# AESADV_1.0 register map
Vendor: Texas Instruments
Peripheral module from a debugger description file (folder mspm33c321x).
Registers are 32-bit, access not given, no defined reset value unless marked. A register's access mark holds for its fields unless they carry their own. Offsets are as the file gives them; lines under a group give offsets from that group; [hi:lo] are bit positions; {n}, {i} and the like mark numbered series; 'fields as' and 'values as' point back to an identical list; <NAME> marks a mode.

## AESADVHP
0x480 AESADVHP_CPU_CONNECT_0 — CPU Connect
0x800 AESADVHP_GPRCM group
  0x00 AESADVHP_PWREN rw — Power enable
    [0] ENABLE — Enable the power
      0=DISABLE (Disable Power); 1=ENABLE (Enable Power)
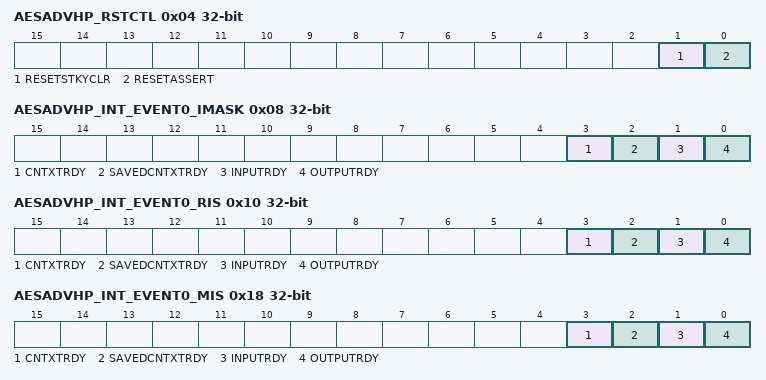
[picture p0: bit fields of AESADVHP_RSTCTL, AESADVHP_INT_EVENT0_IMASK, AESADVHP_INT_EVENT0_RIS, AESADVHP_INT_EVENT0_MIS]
  0x04 AESADVHP_RSTCTL rw — Reset Control
    [1] RESETSTKYCLR — Clear the RESETSTKY bit in the STAT register
      0=NOP (Writing 0 has no effect); 1=CLR (Clear reset sticky bit)
    [0] RESETASSERT — Assert reset to the peripheral
      0=NOP (Writing 0 has no effect); 1=ASSERT (Assert reset)
  0x14 AESADVHP_STAT ro — Status Register
    [16] RESETSTKY — This bit indicates, if the peripheral was reset, since this bit was cleared by RESETSTKYCLR in the RSTCTL register
      0=NORES (The peripheral has not been reset since this bit was last cleared by RESETSTKYCLR in the RSTCTL register); 1=RESET (The peripheral was reset since the last bit clear)
0x1018 AESADVHP_PDBGCTL ro — Peripheral Debug Control
  [0] FREE — Free run control
    1=RUN (The peripheral ignores the state of the Core Halted input)
0x1020 AESADVHP_INT_EVENT0 group
  0x00 AESADVHP_INT_EVENT0_IIDX ro — Interrupt Index Register
    [7:0] STAT — Interrupt index status
      0=NO_INTR (No interrupt pending); 1=OUTPUTRDY (This indicates that the core has an output available to be read out. This should not be used if DMA handshake is used (AES_DMA_HS.DMA_DATA_ACK set to 1)); 2=INPUTRDY (This indicates that the engine can take new input. This should not be used if DMA handshake is used (AES_DMA_HS.DMA_DATA_ACK set to 1)); 3=SAVEDCNTXTRDY (This bit indicates that an AES authentication TAG and/or IV block(s) is/are available for the CPU to retrieve. This bit is only asserted if the save_context bit is set to 1b. The bit is mutually exclusive with the context_ready bit.); 4=CNTXTRDY (This bit indicates that the context data registers can be overwritten, and the CPU is permitted to write new context.)
  0x08 AESADVHP_INT_EVENT0_IMASK rw — Interrupt mask
    [all] fields
      0=CLR (Clear Interrupt Mask); 1=SET (Set Interrrupt Mask)
    [3] CNTXTRDY — This bit indicates that the context data registers can be overwritten, and the CPU is permitted to write next context.
    [2] SAVEDCNTXTRDY — This bit indicates that an AES authentication TAG and/or IV block(s) is/are available for the CPU to retrieve. This bit is only asserted if the save_context bit is set to 1b. The bit is mutually exclusive with the context_ready bit.
    [1] INPUTRDY — This indicates that the engine can take new input. This should not be used if DMA handshake is used (AES_DMA_HS.DMA_DATA_ACK set to 1)
    [0] OUTPUTRDY — This indicates that the core has an output available to be read out. This should not be used if DMA handshake is used (AES_DMA_HS.DMA_DATA_ACK set to 1)
  0x10 AESADVHP_INT_EVENT0_RIS rw — Raw interrupt status
    [3] CNTXTRDY — This bit indicates that the context data registers can be overwritten, and the CPU is permitted to write next context.
      0=CLR (Clear Interrupt Mask); 1=SET (Set Interrrupt Mask)
    [2] SAVEDCNTXTRDY — This bit indicates that an AES authentication TAG and/or IV block(s) is/are available for the CPU to retrieve. This bit is only asserted if the save_context bit is set to 1b. The bit is mutually exclusive with the context_ready bit.
      0=CLR (Clear Interrupt Mask); 1=SET (Set Interrrupt Mask)
    [1] INPUTRDY — This indicates that the engine can take new input. This should not be used if DMA handshake is used (AES_DMA_HS.DMA_DATA_ACK set to 1)
      0=CLR (Clear Interrupt Mask); 1=SET (Set Interrrupt Mask)
    [0] OUTPUTRDY — This indicates that the core has an output available to be read out. This should not be used if DMA handshake is used (AES_DMA_HS.DMA_DATA_ACK set to 1)
      0=CLR (Interrupt did not occur); 1=SET (Interrupt occured)
  0x18 AESADVHP_INT_EVENT0_MIS rw — Masked interrupt status
    fields as AESADVHP_INT_EVENT0.AESADVHP_INT_EVENT0_RIS
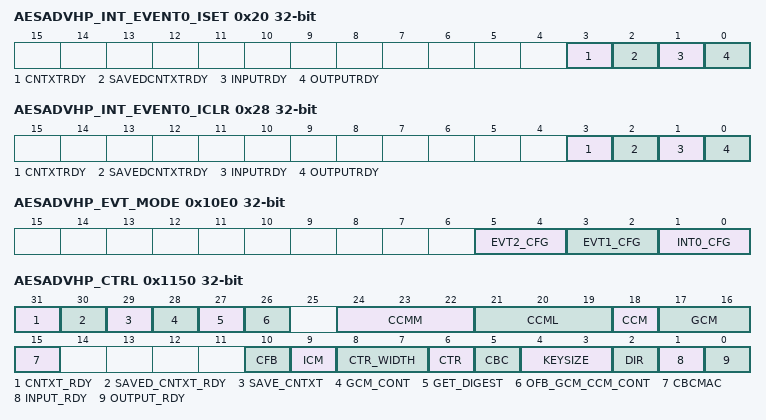
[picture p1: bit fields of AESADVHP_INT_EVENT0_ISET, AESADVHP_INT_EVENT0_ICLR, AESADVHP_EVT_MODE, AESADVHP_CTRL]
  0x20 AESADVHP_INT_EVENT0_ISET rw — Interrupt set
    [3] CNTXTRDY — This bit indicates that the context data registers can be overwritten, and the CPU is permitted to write next context.
      0=CLR (Clear Interrupt Mask); 1=SET (Set Interrrupt Mask)
    [2] SAVEDCNTXTRDY — This bit indicates that an AES authentication TAG and/or IV block(s) is/are available for the CPU to retrieve. This bit is only asserted if the save_context bit is set to 1b. The bit is mutually exclusive with the context_ready bit.
      0=CLR (Clear Interrupt Mask); 1=SET (Set Interrrupt Mask)
    [1] INPUTRDY — This indicates that the engine can take new input.This should not be used if DMA handshake is used (AES_DMA_HS.DMA_DATA_ACK set to 1)
      0=CLR (Clear Interrupt Mask); 1=SET (Set Interrrupt Mask)
    [0] OUTPUTRDY — This indicates that the core has an output available to be read out. This should not be used if DMA handshake is used (AES_DMA_HS.DMA_DATA_ACK set to 1)
      0=NO_EFFECT (Writing 0 has no effect); 1=SET (Set Interrupt)
  0x28 AESADVHP_INT_EVENT0_ICLR rw — Interrupt clear
    [3] CNTXTRDY — This bit indicates that the context data registers can be overwritten, and the CPU is permitted to write next context.
      0=CLR (Clear Interrupt Mask); 1=SET (Set Interrrupt Mask)
    [2] SAVEDCNTXTRDY — This bit indicates that an AES authentication TAG and/or IV block(s) is/are available for the CPU to retrieve. This bit is only asserted if the save_context bit is set to 1b. The bit is mutually exclusive with the context_ready bit.
      0=CLR (Clear Interrupt Mask); 1=SET (Set Interrrupt Mask)
    [1] INPUTRDY — This indicates that the engine can take new input. This should not be used if DMA handshake is used (AES_DMA_HS.DMA_DATA_ACK set to 1)
      0=CLR (Clear Interrupt Mask); 1=SET (Set Interrrupt Mask)
    [0] OUTPUTRDY — This indicates that the core has an output available to be read out. This should not be used if DMA handshake is used (AES_DMA_HS.DMA_DATA_ACK set to 1)
      0=NO_EFFECT (Writing 0 has no effect); 1=CLR (Clear Interrupt)
0x1050 AESADVHP_INT_EVENT1 group
  0x00 AESADVHP_INT_EVENT1_IIDX ro — Interrupt Index Register
    [7:0] STAT — Interrupt index status
      0=NO_INTR (No interrupt pending); 1=TRIG0 (AES trigger 0 DMA (Data Input trigger))
  0x08 AESADVHP_INT_EVENT1_IMASK rw — Interrupt mask
    [0] TRIG0 — TRIG0 event mask.
      0=CLR (Clear Interrupt Mask); 1=SET (Set Interrrupt Mask)
  0x10 AESADVHP_INT_EVENT1_RIS rw — Raw interrupt status
    [0] TRIG0 — TRIG0 event
      0=CLR (Interrupt did not occur); 1=SET (Interrupt occured)
  0x18 AESADVHP_INT_EVENT1_MIS rw — Masked interrupt status
    fields as AESADVHP_INT_EVENT1.AESADVHP_INT_EVENT1_RIS
  0x20 AESADVHP_INT_EVENT1_ISET rw — Interrupt set
    [0] TRIG0
      0=NO_EFFECT (Writing 0 has no effect); 1=SET (Set Interrupt)
  0x28 AESADVHP_INT_EVENT1_ICLR rw — Interrupt clear
    [0] TRIG0 — TRIG0 event
      values as AESADVHP_INT_EVENT0.AESADVHP_INT_EVENT0_ICLR.OUTPUTRDY
0x1080 AESADVHP_INT_EVENT2 group
  0x00 AESADVHP_INT_EVENT2_IIDX ro — Interrupt Index Register
    [7:0] STAT — Interrupt index status
      0=NO_INTR (No interrupt pending); 1=TRIG1 (AES DMA Trigger 1 (Data Output trigger))
  0x08 AESADVHP_INT_EVENT2_IMASK rw — Interrupt mask
    [0] TRIG1 — TRIG1 event mask.
      0=CLR (Clear Interrupt Mask); 1=SET (Set Interrrupt Mask)
  0x10 AESADVHP_INT_EVENT2_RIS rw — Raw interrupt status
    [0] TRIG1 — TRIG1 event
      0=CLR (Interrupt did not occur); 1=SET (Interrupt occured)
  0x18 AESADVHP_INT_EVENT2_MIS rw — Masked interrupt status
    fields as AESADVHP_INT_EVENT2.AESADVHP_INT_EVENT2_RIS
  0x20 AESADVHP_INT_EVENT2_ISET rw — Interrupt set
    [0] TRIG1 — TRIG1 event
      0=NO_EFFECT (Writing 0 has no effect); 1=SET (Set Interrupt)
  0x28 AESADVHP_INT_EVENT2_ICLR rw — Interrupt clear
    [0] TRIG1 — TRIG1 event
      values as AESADVHP_INT_EVENT0.AESADVHP_INT_EVENT0_ICLR.OUTPUTRDY
0x10E0 AESADVHP_EVT_MODE ro — Event Mode
  [all] fields
    0=DISABLE (The interrupt or event line is disabled.); 1=SOFTWARE (The interrupt or event line is in software mode. Software must clear the RIS.); 2=HARDWARE (The interrupt or event line is in hardware mode. The hardware (another module) clears automatically the associated RIS flag.)
  [5:4] EVT2_CFG — Event line mode select for event corresponding to [IPSTANDARD.INT_EVENT2]
  [3:2] EVT1_CFG — Event line mode select for event corresponding to [IPSTANDARD.INT_EVENT1]
  [1:0] INT0_CFG — Event line mode select for event corresponding to [IPSTANDARD.INT_EVENT0]
0x1100 AESADVHP_GCMCCM_TAG0 — CBC-MAC third key (LSW) / GCM & CCM Intermediate TAG (LSW)
0x1104 AESADVHP_GCMCCM_TAG1 — CBC-MAC third key / GCM & CCM Intermediate TAG
0x1108 AESADVHP_GCMCCM_TAG2 — CBC-MAC third key / GCM & CCM Intermediate TAG
0x110C AESADVHP_GCMCCM_TAG3 — CBC-MAC third key (MSW) / GCM & CCM Intermediate TAG (MSW)
0x1110 AESADVHP_GHASH_H0 — CCM & CBC-MAC second key (LSW) / GCM Hash Key input (LSW)
0x1114 AESADVHP_GHASH_H1 — CCM & CBC-MAC second key / GCM Hash Key input
0x1118 AESADVHP_GHASH_H2 — CCM & CBC-MAC second key / GCM Hash Key input
0x111C AESADVHP_GHASH_H3 — CCM & CBC-MAC second key (MSW) / GCM Hash Key input (MSW)
0x1120 AESADVHP_KEY0 — KEY (LSW)
{0x1120+4i} AESADVHP_KEY{i} (i=1..6) — KEY
0x113C AESADVHP_KEY7 — KEY (MSW)
0x1140 AESADVHP_IV0 — IV (LSW)
{0x1140+4i} AESADVHP_IV{i} (i=1..3) — IV
0x1150 AESADVHP_CTRL access per field — Input/Output Buffer Control and Mode selection
  [31] CNTXT_RDY ro — If 1b, this read-only status bit indicates that the context data registers can be overwritten, and the CPU is permitted to write the next context.
    0=NOTREADY; 1=READY
  [30] SAVED_CNTXT_RDY ro — If 1b, this read-only status bit indicates that an AES authentication TAG and/or IV block(s) is/are available for the Host to retrieve. This bit is only asserted if the save_context bit is set to 1b. The bit is mutually exclusive with the context_ready bit.
    0=NOTREADY; 1=READY
  [29] SAVE_CNTXT rw — This bit is used to indicate that an authentication TAG or result IV needs to be stored as a result context. If this bit is set, context output DMA and/or interrupt will be asserted if the operation is finished, and related signals are enabled. Typically, this value must be set for authentication modes returning a TAG (CBC-MAC, GCM and CCM), or for basic encryption modes that require future continuation with the current result IV. If this bit is set, the engine will hold its full context until the TAG and/or IV registers are read. Only after reading the TAG or IV, a new DMA request for a new (input) context will be asserted. If this bit is not set, the engine will assert the context input DMA request signal directly after starting to process the last block with the current context.
    0=NO_EFFECT; 1=ENABLE
  [28] GCM_CONT rw — Continue processing of an interrupted AES-GCM or AES-CCM operation in the crypto/payload phase. Set this write-only signal to 1b together with the regular mode bit settings for a GCM or CCM operation, to continue processing from the next full block (128 bits) boundary. Before setting this bit all applicable context to resume processing must have been loaded into the engine: Keys, IV, intermediate digest/TAG and block counter. The mode can be written together with this bit, as it is part of the same register.
    0=NO_EFFECT; 1=ENABLE
  [27] GET_DIGEST rw — Interrupt processing and generate an intermediate digest during an AES-GCM or AES-CCM operation. Set this write-only signal to 1b to interrupt GCM or CCM processing at the next full block (128 bits) boundary. An intermediate digest may be requested during the encryption/decryption data phase or in the AAD phase. Note: Interruption can only be done on full block (128 bits) boundaries. The minimum number of remaining bytes to resume and finalize the operation, must be greater than or equal to 1.
    0=NO_EFFECT; 1=ENABLE
  [26] OFB_GCM_CCM_CONT rw — This bit has a dual use, depending on the selection of CCM/GCM, see bits [18:16]. If CCM/GCM is not selected: If this bit is set to 1b, full block AES output feedback mode (OFB-128) is selected. If CCM/GCM is selected: Continue processing of an interrupted AES-GCM or AES-CCM operation in the AAD phase. Set this write-only signal to 1b together with the regular mode bit settings for a GCM or CCM operation, to continue processing from the next full AAD block (128 bits) boundary. Before setting this bit all applicable context to resume processing must have been loaded into the engine: Keys, IV, intermediate digest/TAG, block counter and the CCM align data word (the latter is for CCM mode only). The mode can be written together with this bit, as it is part of the same register.
    1=OFB (Enable OFB); 1=GCM_CCM_CONTINUE (Continue GCM/CCM processing in AAD phase)
  [24:22] CCMM rw — Defines M that indicates the length of the authentication field for CCM operations; the authentication field length equals two times (the value of CCM-M plus one). Note: The EIP-39 always returns a 128-bit authentication field, of which the M least significant bytes are valid. All values are supported.
    0=MINIMUM (Length is 1); 7=MAXIMUM (Length is 8)
  [21:19] CCML rw — Defines L that indicates the width of the length field for CCM operations; the length field in bytes equals the value of CMM-L plus one. All values are supported.
    0=MINIMUM (Length is 1); 7=MAXIMUM (Length is 8)
  [18] CCM rw — If set to 1b, AES-CCM is selected, this is a combined mode, using AES for both authentication and encryption. In addition to the CCM bit, the CTR mode bit must be set such that AES-CTR is enabled. Other combinations with CCM are invalid.
    0=DISABLE (Disable CBC mode); 1=ENABLE (Select CBC mode)
  [17:16] GCM rw — If not set to 00b, AES-GCM mode is selected, this is a combined mode, using the Galois field multiplier GF(2128) for authentication and AES-CTR mode for encryption, the bits specify the GCM mode: 01b = GHASH with H loaded and Y0-encrypted forced to zero 10b = GHASH with H loaded and Y0-encrypted calculated internally 11b = Autonomous GHASH (both H and Y0-encrypted calculated internally) Note: Besides GCM, the CTR mode bits must also be set to 1b to enable GCM with AES-CTR; if the CTR bit is not set a GHASH (authentication) only operation is performed. A GHASH only operation is only allowed if the GCM mode is set to '01b' and the direction bit is set to '0b'. Other modes may not be selected in combination with GCM. Table 14 below shows the valid combinations for the GCM and CTR mode bits, all other options are invalid and must not be selected.
    1=FORCE_ZERO (GHASH with H loaded and Y0-encrypted forced to 0.); 2=LOAD_HASH_KEY (GHASH with H loaded and Y0-encrypted calculated internally); 3=AUTONOMOUS (Autonomous GHASH (both H and Y0-encrypted calculated internally))
  [15] CBCMAC rw — If set to 1b, AES-CBC MAC is selected, the Direction bit must be set to 1 for this mode.
    0=DISABLE (Disable CBC mode); 1=ENABLE (Select CBC mode)
  [10] CFB rw — If set to 1b, AES cipher feedback mode CFB is selected. Use the ctr_width field to specify the feedback width.
    0=DISABLE (Disable CBC mode); 1=ENABLE (Select CBC mode)
  [9] ICM rw — When the CFB bit is set, specifies the CFB mode feedback width:
    0=DISABLE (Disable CBC mode); 1=ENABLE (Select CBC mode)
  [8:7] CTR_WIDTH rw — When the CTR bit is set, specifies the counter width for AES-CTR mode. When the CFB bit is set, specifies the CFB mode feedback width:
    0=CTR32 (32-bit counter); 0=CFB128 (CFB-128 mode); 1=CTR64 (64-bit counter); 2=CTR96 (96-bit counter); 3=CTR128 (128-bit counter)
  [6] CTR rw — If set to 1b, AES counter mode (CTR) is selected. Note: This bit must also be set for GCM and CCM, when encryption/decryption is required.
    0=DISABLE (Disable CBC mode); 1=ENABLE (Select CBC mode)
  [5] CBC rw — If set to 1b, cipher-block-chaining (CBC) mode is selected.
    0=DISABLE (Disable CBC mode); 1=ENABLE (Select CBC mode)
  [4:3] KEYSIZE rw — Specifies the encryption strength / key width
    1=K128 (128-bit key); 3=K256 (256-bit key)
  [2] DIR rw — Direction. If set to 1b an encrypt operation is performed. If set to 0b a decrypt operation is performed. Note: This bit must be written with a 1b when CBC-MAC is selected.
    0=DECRYPT (Decryption); 1=ENCRYPT (Encryption)
  [1] INPUT_RDY ro — Ready for input. If 1b, this read-only status bit indicates that the 16-byte input buffer is empty, and the CPU is permitted to write the next block of data. After reset, this bit is 0. After writing a context, this bit will become 1b.
    0=NOTEMPTY (Not Ready); 1=EMPTY (Ready)
  [0] OUTPUT_RDY ro — Output Ready. If 1b, this read-only status bit indicates that an AES output block is available for the CPU to retrieve.
    0=NOTREADY; 1=READY
0x1154 AESADVHP_C_LENGTH_0 — Crypto data length (LSW)
0x1158 AESADVHP_C_LENGTH_1 rw — Crypto data length (MSW)
  [28:0] DATA — Bits [60:0] of the crypto length registers (LSW and MSW) store the cryptographic data length in bytes for all modes. Once processing with this context is started, this length decrements to zero. Data lengths up to (261-1) bytes are allowed. For GCM, any value up to 236-32 bytes can be used. This is because a 32-bit counter mode is used; the maximum number of 128-bit blocks is 232-2, resulting in a maximum number of bytes of 236-32. A write to this register triggers the engine to start using this context. This is valid for all modes except GCM and CCM. Note that for the combined modes, this length does not include the authentication only data; the authentication length is specified in the AES_AAD_LENGTH register below. All modes must have a length > 0. For the combined modes, it is allowed to have one of the lengths equal to zero. For the basic encryption modes (ECB/CBC/CTR/ICM/CFB/OFB) it is allowed to program zero to the length field; in that case the length is assumed infinite. All data must be byte (8-bit) aligned for stream cipher modes; bit aligned data streams are not supported. For block cipher modes, the data length must be programmed in multiples of the block cipher size, 16 bytes.
0x115C AESADVHP_AAD_LENGTH — AAD Data Length
0x1160 AESADVHP_DATA0 — Data input (LSW) / Data output (LSW)
0x1164 AESADVHP_DATA1 — Data input / Data output
0x1168 AESADVHP_DATA2 — Data input / Data output
0x116C AESADVHP_DATA3 — Data input (LSW) / Data output (MSW)
0x1170 AESADVHP_TAG0 — Hash result (LSW)
0x1174 AESADVHP_TAG1 — Hash result
0x1178 AESADVHP_TAG2 — Hash result
0x117C AESADVHP_TAG3 — Hash result (MSW)
0x1180 AESADVHP_STATUS ro — Status
  [0] KEYWR — Key write status. 0 - user write to KEY register is allowed. 1 - user write to KEY register is ignored. In order to allow user write, perform a module reset.
    0=ENABLED (User write to KEY MMR is allowed); 1=DISABLED (User write to KEY MMR is disabled. Writing has no effect.)
0x1184 AESADVHP_DATA_IN — Data in alias register
0x1188 AESADVHP_DATA_OUT — Data out alias register
0x11D0 AESADVHP_FORCE_IN_AV — Data control register for input data
0x11D4 AESADVHP_CCM_ALN_WRD — AES-CCM AAD alignment data word
0x11D8 AESADVHP_BLK_CNT0 — Internal block counter (LSW)
0x11DC AESADVHP_BLK_CNT1 rw — Internal block counter (MSW)
  [23:0] DATA — Internal block counter for AES GCM and CCM operations. These bits read the block count value that represents the number of blocks to go. This value is valid with saved_context_ready after a request for an intermediate GCM/CCM digest. Writing these registers will restore the internal block counter to the programmed value. This only needs to be done to prepare the engine to continue processing of an interrupted GCM or CCM operation. Also refer to the get_digest and gcm_ccm_continue bits in AES_CTRL register.
0x11F4 AESADVHP_DMA_HS rw — Control register for DMA handshaking
  [0] DMA_DATA_ACK — When this bit is 0b, input and output data acknowledge is I/O register based, as specified in the description of the AES_DATA_IN_n / AES_DATA_OUT_n registers. When this bit is 1b, input and ouput data acknowledge is based on DMA handshake signals.
    0=DMA_DISABLE (Disable DMA based data handshake); 1=DMA_ENABLE (Enables DMA based handshake)
0x11F8 AESADVHP_OPTIONS — EIP-39 options register
0x11FC AESADVHP_VERSION — EIP-39 version register
